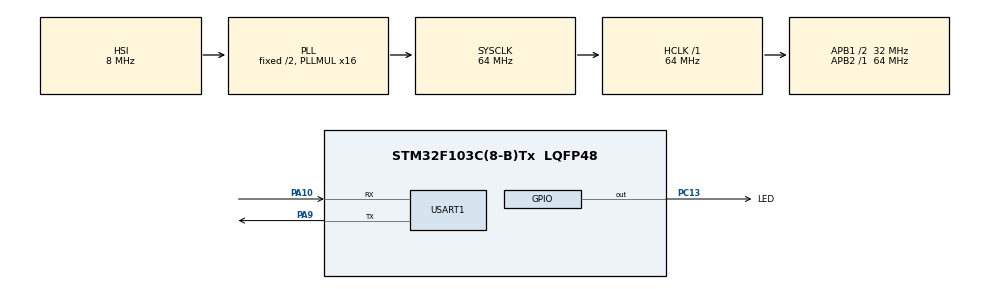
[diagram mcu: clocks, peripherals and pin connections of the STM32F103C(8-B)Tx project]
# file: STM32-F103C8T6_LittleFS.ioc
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Dma.Request0=USART1_RX
Dma.USART1_RX.0.Direction=DMA_PERIPH_TO_MEMORY
Dma.USART1_RX.0.Instance=DMA1_Channel5
Dma.USART1_RX.0.MemDataAlignment=DMA_MDATAALIGN_BYTE
Dma.USART1_RX.0.MemInc=DMA_MINC_ENABLE
Dma.USART1_RX.0.Mode=DMA_CIRCULAR
Dma.USART1_RX.0.PeriphDataAlignment=DMA_PDATAALIGN_BYTE
Dma.USART1_RX.0.PeriphInc=DMA_PINC_DISABLE
Dma.USART1_RX.0.Priority=DMA_PRIORITY_LOW
Mcu.Family=STM32F1
Mcu.Name=STM32F103C(8-B)Tx
Mcu.Package=LQFP48
NVIC.DMA1_Channel5_IRQn=true\:0\:0\:false\:false\:true\:false\:true\:true
NVIC.PriorityGroup=NVIC_PRIORITYGROUP_4
PA9.Mode=Asynchronous
PA9.Signal=USART1_TX
PA10.Mode=Asynchronous
PA10.Signal=USART1_RX
PC13-TAMPER-RTC.GPIO_Label=LED
PC13-TAMPER-RTC.GPIO_Speed=GPIO_SPEED_FREQ_MEDIUM
PC13-TAMPER-RTC.PinState=GPIO_PIN_SET
PC13-TAMPER-RTC.Signal=GPIO_Output
PC14-OSC32_IN.Mode=LSE-External-Oscillator
PC14-OSC32_IN.Signal=RCC_OSC32_IN
PC15-OSC32_OUT.Mode=LSE-External-Oscillator
PC15-OSC32_OUT.Signal=RCC_OSC32_OUT
PD0-OSC_IN.Mode=HSE-External-Oscillator
PD0-OSC_IN.Signal=RCC_OSC_IN
PD1-OSC_OUT.Mode=HSE-External-Oscillator
PD1-OSC_OUT.Signal=RCC_OSC_OUT
ProjectManager.HeapSize=0x400
ProjectManager.StackSize=0x800
ProjectManager.TargetToolchain=STM32CubeIDE
RCC.AHBFreq_Value=64000000
RCC.APB1CLKDivider=RCC_HCLK_DIV2
RCC.APB1Freq_Value=32000000
RCC.APB1TimFreq_Value=64000000
RCC.APB2Freq_Value=64000000
RCC.APB2TimFreq_Value=64000000
RCC.HCLKFreq_Value=64000000
RCC.PLLMUL=RCC_PLL_MUL16
RCC.SYSCLKFreq_VALUE=64000000
RCC.SYSCLKSource=RCC_SYSCLKSOURCE_PLLCLK
RCC.USBFreq_Value=64000000
TIM4.Channel-PWM\ Generation1\ No\ Output=TIM_CHANNEL_1
TIM4.Prescaler=64-1
USART1.VirtualMode=VM_ASYNC
VP_TIM4_VS_no_output1.Mode=PWM Generation1 No Output
board=custom

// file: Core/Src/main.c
/* USER CODE BEGIN Header */
/**
  ******************************************************************************
  * @file           : main.c
  * @brief          : Main program body
  ******************************************************************************
  * @attention
  *
  * Copyright (c) 2023 STMicroelectronics.
  * All rights reserved.
  *
  * This software is licensed under terms that can be found in the LICENSE file
  * in the root directory of this software component.
  * If no LICENSE file comes with this software, it is provided AS-IS.
  *
  ******************************************************************************
  */
/* USER CODE END Header */
#include "main.h"

/* USER CODE BEGIN Includes */
#include <stdio.h> // EOF
#include <string.h> // strlen()
#include "command_line.h"
#include "littlefs_interface.h"
/* USER CODE END Includes */

TIM_HandleTypeDef htim4;

UART_HandleTypeDef huart1;
DMA_HandleTypeDef hdma_usart1_rx;

void SystemClock_Config(void);
static void MX_GPIO_Init(void);
static void MX_DMA_Init(void);
static void MX_TIM4_Init(void);
static void MX_USART1_UART_Init(void);

/* USER CODE BEGIN 0 */

// DMA Buffer for usart1 RX
#define USART1_RX_DMA_BUFFER_SIZE 1030 // any size will do, but we may want to choose X-Modem receive size
uint8_t usart1_rx_dma_buffer[USART1_RX_DMA_BUFFER_SIZE];

// Implement a get_byte(void) function that utilizes a circular DMA RX buffer that:
// 1) Tests if data is available in the DMA RX buffer
// 2) Pulls and returns the data
// 3) Manages an index_out value for next removal of data
// 4) As a non-blocking function, return EOF when no bytes are available, else returns data byte
static uint16_t index_out = 0; // next byte to remove from the DMA RX buffer

// Return the number of bytes waiting in the DMA RX buffer
uint16_t usart1_rx_count(void)
{
	uint16_t index_in = USART1_RX_DMA_BUFFER_SIZE - huart1.hdmarx->Instance->CNDTR;
	if(index_in >= index_out) return index_in - index_out;
	return USART1_RX_DMA_BUFFER_SIZE - index_out + index_in; // wrapped
}

int __io_getchar(void)
{
	uint16_t index_in = USART1_RX_DMA_BUFFER_SIZE - huart1.hdmarx->Instance->CNDTR;
	if(index_in == index_out) return EOF;
	// Else, we have a byte in buffer to return
	uint8_t data = usart1_rx_dma_buffer[index_out];
	// advance index
	index_out++;
	// wrap index when necessary
	if(index_out >= USART1_RX_DMA_BUFFER_SIZE) index_out = 0;
	return data;
}

// Define serial input and output functions using UART2
int __io_putchar(int ch)
{
    HAL_UART_Transmit(&huart1, (uint8_t *)&ch, 1, 1000);
    return 1;
}
/* USER CODE END 0 */

int main(void)
{

  /* MCU Configuration--------------------------------------------------------*/

  /* Reset of all peripherals, Initializes the Flash interface and the Systick. */
  HAL_Init();

  /* Configure the system clock */
  SystemClock_Config();

  /* Initialize all configured peripherals */
  MX_GPIO_Init();
  MX_DMA_Init();
  MX_TIM4_Init();
  MX_USART1_UART_Init();
  /* USER CODE BEGIN 2 */
  //printf("Welcome - NUCLEO-F103RB_LittleFS\n");

  /* Put UART peripheral in DMA reception mode ###########################*/
  if (HAL_UART_Receive_DMA(&huart1, usart1_rx_dma_buffer, USART1_RX_DMA_BUFFER_SIZE) != HAL_OK)
  {
    /* Transfer error in reception process */
    Error_Handler();
  }

  /* Unlock the Flash to enable the flash control register access *************/
  HAL_FLASH_Unlock();

  // Initialize LittleFS
  lfs_init();

  /* USER CODE END 2 */

  /* Infinite loop */
  /* USER CODE BEGIN WHILE */
  cl_setup();
  while (1)
  {
//	  printf("Hello\n");
//		HAL_GPIO_WritePin(LED_GPIO_Port, LED_Pin, GPIO_PIN_SET);
//		HAL_Delay(500);
//		HAL_GPIO_WritePin(LED_GPIO_Port, LED_Pin, GPIO_PIN_RESET);
//		HAL_Delay(500);
		cl_loop();
    /* USER CODE END WHILE */

  }
}

void SystemClock_Config(void)
{
  RCC_OscInitTypeDef RCC_OscInitStruct = {0};
  RCC_ClkInitTypeDef RCC_ClkInitStruct = {0};

  /** Initializes the RCC Oscillators according to the specified parameters
  * in the RCC_OscInitTypeDef structure.
  */
  RCC_OscInitStruct.OscillatorType = RCC_OSCILLATORTYPE_HSI;
  RCC_OscInitStruct.HSIState = RCC_HSI_ON;
  RCC_OscInitStruct.HSICalibrationValue = RCC_HSICALIBRATION_DEFAULT;
  RCC_OscInitStruct.PLL.PLLState = RCC_PLL_ON;
  RCC_OscInitStruct.PLL.PLLSource = RCC_PLLSOURCE_HSI_DIV2;
  RCC_OscInitStruct.PLL.PLLMUL = RCC_PLL_MUL16;
  if (HAL_RCC_OscConfig(&RCC_OscInitStruct) != HAL_OK)
  {
    Error_Handler();
  }

  /** Initializes the CPU, AHB and APB buses clocks
  */
  RCC_ClkInitStruct.ClockType = RCC_CLOCKTYPE_HCLK|RCC_CLOCKTYPE_SYSCLK
                              |RCC_CLOCKTYPE_PCLK1|RCC_CLOCKTYPE_PCLK2;
  RCC_ClkInitStruct.SYSCLKSource = RCC_SYSCLKSOURCE_PLLCLK;
  RCC_ClkInitStruct.AHBCLKDivider = RCC_SYSCLK_DIV1;
  RCC_ClkInitStruct.APB1CLKDivider = RCC_HCLK_DIV2;
  RCC_ClkInitStruct.APB2CLKDivider = RCC_HCLK_DIV1;

  if (HAL_RCC_ClockConfig(&RCC_ClkInitStruct, FLASH_LATENCY_2) != HAL_OK)
  {
    Error_Handler();
  }
}

static void MX_TIM4_Init(void)
{

  TIM_MasterConfigTypeDef sMasterConfig = {0};
  TIM_OC_InitTypeDef sConfigOC = {0};

  htim4.Instance = TIM4;
  htim4.Init.Prescaler = 64-1;
  htim4.Init.CounterMode = TIM_COUNTERMODE_UP;
  htim4.Init.Period = 65535;
  htim4.Init.ClockDivision = TIM_CLOCKDIVISION_DIV1;
  htim4.Init.AutoReloadPreload = TIM_AUTORELOAD_PRELOAD_DISABLE;
  if (HAL_TIM_PWM_Init(&htim4) != HAL_OK)
  {
    Error_Handler();
  }
  sMasterConfig.MasterOutputTrigger = TIM_TRGO_RESET;
  sMasterConfig.MasterSlaveMode = TIM_MASTERSLAVEMODE_DISABLE;
  if (HAL_TIMEx_MasterConfigSynchronization(&htim4, &sMasterConfig) != HAL_OK)
  {
    Error_Handler();
  }
  sConfigOC.OCMode = TIM_OCMODE_PWM1;
  sConfigOC.Pulse = 0;
  sConfigOC.OCPolarity = TIM_OCPOLARITY_HIGH;
  sConfigOC.OCFastMode = TIM_OCFAST_DISABLE;
  if (HAL_TIM_PWM_ConfigChannel(&htim4, &sConfigOC, TIM_CHANNEL_1) != HAL_OK)
  {
    Error_Handler();
  }
  /* USER CODE BEGIN TIM4_Init 2 */
  HAL_TIM_Base_Start(&htim4);
  /* USER CODE END TIM4_Init 2 */

}

static void MX_USART1_UART_Init(void)
{

  huart1.Instance = USART1;
  huart1.Init.BaudRate = 115200;
  huart1.Init.WordLength = UART_WORDLENGTH_8B;
  huart1.Init.StopBits = UART_STOPBITS_1;
  huart1.Init.Parity = UART_PARITY_NONE;
  huart1.Init.Mode = UART_MODE_TX_RX;
  huart1.Init.HwFlowCtl = UART_HWCONTROL_NONE;
  huart1.Init.OverSampling = UART_OVERSAMPLING_16;
  if (HAL_UART_Init(&huart1) != HAL_OK)
  {
    Error_Handler();
  }

}

static void MX_DMA_Init(void)
{

  /* DMA controller clock enable */
  __HAL_RCC_DMA1_CLK_ENABLE();

  /* DMA interrupt init */
  /* DMA1_Channel5_IRQn interrupt configuration */
  HAL_NVIC_SetPriority(DMA1_Channel5_IRQn, 0, 0);
  HAL_NVIC_EnableIRQ(DMA1_Channel5_IRQn);

}

static void MX_GPIO_Init(void)
{
  GPIO_InitTypeDef GPIO_InitStruct = {0};

  /* GPIO Ports Clock Enable */
  __HAL_RCC_GPIOC_CLK_ENABLE();
  __HAL_RCC_GPIOD_CLK_ENABLE();
  __HAL_RCC_GPIOA_CLK_ENABLE();

  /*Configure GPIO pin Output Level */
  HAL_GPIO_WritePin(LED_GPIO_Port, LED_Pin, GPIO_PIN_SET);

  /*Configure GPIO pin : LED_Pin */
  GPIO_InitStruct.Pin = LED_Pin;
  GPIO_InitStruct.Mode = GPIO_MODE_OUTPUT_PP;
  GPIO_InitStruct.Pull = GPIO_NOPULL;
  GPIO_InitStruct.Speed = GPIO_SPEED_FREQ_MEDIUM;
  HAL_GPIO_Init(LED_GPIO_Port, &GPIO_InitStruct);

}

void Error_Handler(void)
{
  __disable_irq();
  while (1)
  {
  }
}
